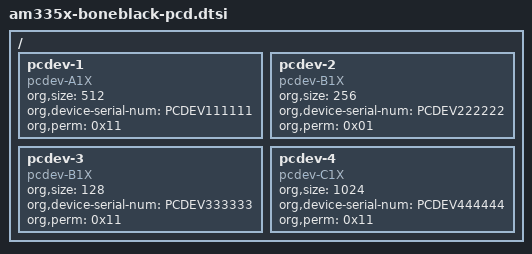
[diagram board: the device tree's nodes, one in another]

/ {
	pcdev-1 {
		compatible = "pcdev-A1X";
		org,size = <512>;
		org,device-serial-num = "PCDEV111111";
		org,perm = <0x11>;
	};

	pcdev-2 {
		compatible = "pcdev-B1X";
		org,size = <256>;
		org,device-serial-num = "PCDEV222222";
		org,perm = <0x01>;
	};

	pcdev-3 {
		compatible = "pcdev-B1X";
		org,size = <128>;
		org,device-serial-num = "PCDEV333333";
		org,perm = <0x11>;
	};

	pcdev-4 {
		compatible = "pcdev-C1X";
		org,size = <1024>;
		org,device-serial-num = "PCDEV444444";
		org,perm = <0x11>;
	};
};
